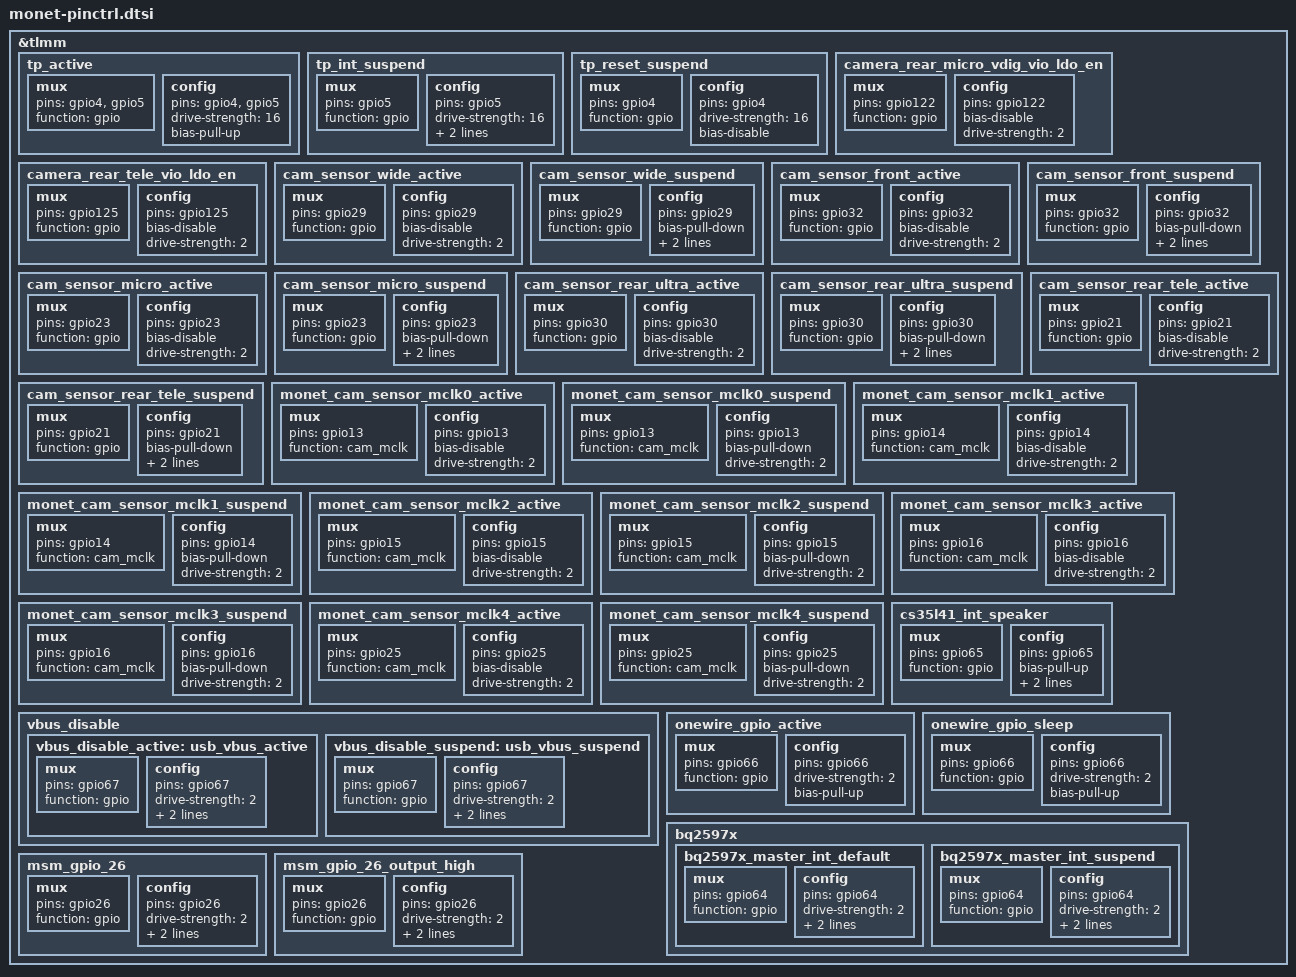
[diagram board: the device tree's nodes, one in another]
/*For J9 pinctrl overlay*/

&tlmm {
	tp_active: tp_active {
		mux {
				pins = "gpio4", "gpio5";
				function = "gpio";
		};

		config {
				pins = "gpio4", "gpio5";
				drive-strength = <16>;
				bias-pull-up;
		};
	};

	tp_int_suspend: tp_int_suspend {
		mux {
				pins = "gpio5";
				function = "gpio";
		};
		config {
				pins = "gpio5";
				drive-strength = <16>;
				bias-pull-up;
				input-enable;
		};
	};

	tp_reset_suspend: tp_reset_suspend {
		mux {
				pins = "gpio4";
				function = "gpio";
		};
		config {
				pins = "gpio4";
				drive-strength = <16>;
				bias-disable;
		};
	};

	camera_rear_micro_vdig_vio_ldo_en: camera_rear_micro_vdig_vio_ldo_en {
		mux {
			pins = "gpio122";
			function = "gpio";
		};

		config {
			pins = "gpio122";
			bias-disable; /* No PULL */
			drive-strength = <2>; /* 2 MA */
		};
	};

	camera_rear_tele_vio_ldo_en: camera_rear_tele_vio_ldo_en {
		mux {
			pins = "gpio125";
			function = "gpio";
		};

		config {
			pins = "gpio125";
			bias-disable; /* No PULL */
			drive-strength = <2>; /* 2 MA */
		};
	};

	cam_sensor_wide_active: cam_sensor_wide_active {
		/* RESET WIDE */
		mux {
			pins = "gpio29";
			function = "gpio";
		};

		config {
			pins = "gpio29";
			bias-disable; /* No PULL */
			drive-strength = <2>; /* 2 MA */
		};
	};

	cam_sensor_wide_suspend: cam_sensor_wide_suspend {
		mux {
			pins = "gpio29";
			function = "gpio";
		};

		config {
			pins = "gpio29";
			bias-pull-down; /* PULL DOWN */
			drive-strength = <2>; /* 2 MA */
			output-low;
		};
	};

	cam_sensor_front_active: cam_sensor_front_active {
		/* RESET FRONT */
		mux {
			pins = "gpio32";
			function = "gpio";
		};

		config {
			pins = "gpio32";
			bias-disable; /* No PULL */
			drive-strength = <2>; /* 2 MA */
		};
	};

	cam_sensor_front_suspend: cam_sensor_front_suspend {
		/* RESET FRONT */
		mux {
			pins = "gpio32";
			function = "gpio";
		};

		config {
			pins = "gpio32";
			bias-pull-down; /* PULL DOWN */
			drive-strength = <2>; /* 2 MA */
			output-low;
		};
	};

	cam_sensor_micro_active: cam_sensor_micro_active {
		/* RESET MICRO */
		mux {
			pins = "gpio23";
			function = "gpio";
		};

		config {
			pins = "gpio23";
			bias-disable; /* No PULL */
			drive-strength = <2>; /* 2 MA */
		};
	};

	cam_sensor_micro_suspend: cam_sensor_micro_suspend {
		/* RESET MICRO */
		mux {
			pins = "gpio23";
			function = "gpio";
		};

		config {
			pins = "gpio23";
			bias-pull-down; /* PULL DOWN */
			drive-strength = <2>; /* 2 MA */
			output-low;
		};
	};

	cam_sensor_rear_ultra_active: cam_sensor_rear_ultra_active {
		/* RESET ULTRA */
		mux {
			pins = "gpio30";
			function = "gpio";
		};

		config {
			pins = "gpio30";
			bias-disable; /* No PULL */
			drive-strength = <2>; /* 2 MA */
		};
	};

	cam_sensor_rear_ultra_suspend: cam_sensor_rear_ultra_suspend {
		/* RESET ULTRA */
		mux {
			pins = "gpio30";
			function = "gpio";
		};

		config {
			pins = "gpio30";
			bias-pull-down; /* PULL DOWN */
			drive-strength = <2>; /* 2 MA */
			output-low;
		};
	};

	cam_sensor_rear_tele_active: cam_sensor_rear_tele_active {
		/* RESET TELE */
		mux {
			pins = "gpio21";
			function = "gpio";
		};

		config {
			pins = "gpio21";
			bias-disable; /* No PULL */
			drive-strength = <2>; /* 2 MA */
		};
	};

	cam_sensor_rear_tele_suspend: cam_sensor_rear_tele_suspend {
		/* RESET TELE */
		mux {
			pins = "gpio21";
			function = "gpio";
		};

		config {
			pins = "gpio21";
			bias-pull-down; /* PULL DOWN */
			drive-strength = <2>; /* 2 MA */
			output-low;
		};
	};

	monet_cam_sensor_mclk0_active: monet_cam_sensor_mclk0_active {
		/* MCLK0 */
		mux {
			pins = "gpio13";
			function = "cam_mclk";
		};

		config {
			pins = "gpio13";
			bias-disable; /* No PULL */
			drive-strength = <2>; /* 2 MA */
		};
	};

	monet_cam_sensor_mclk0_suspend: monet_cam_sensor_mclk0_suspend {
		/* MCLK0 */
		mux {
			pins = "gpio13";
			function = "cam_mclk";
		};

		config {
			pins = "gpio13";
			bias-pull-down; /* PULL DOWN */
			drive-strength = <2>; /* 2 MA */
		};
	};

	monet_cam_sensor_mclk1_active: monet_cam_sensor_mclk1_active {
		/* MCLK1 */
		mux {
			pins = "gpio14";
			function = "cam_mclk";
		};

		config {
			pins = "gpio14";
			bias-disable; /* No PULL */
			drive-strength = <2>; /* 2 MA */
		};
	};

	monet_cam_sensor_mclk1_suspend: monet_cam_sensor_mclk1_suspend {
		/* MCLK1 */
		mux {
			pins = "gpio14";
			function = "cam_mclk";
		};

		config {
			pins = "gpio14";
			bias-pull-down; /* PULL DOWN */
			drive-strength = <2>; /* 2 MA */
		};
	};

	monet_cam_sensor_mclk2_active: monet_cam_sensor_mclk2_active {
		/* MCLK2 */
		mux {
			pins = "gpio15";
			function = "cam_mclk";
		};

		config {
			pins = "gpio15";
			bias-disable; /* No PULL */
			drive-strength = <2>; /* 2 MA */
		};
	};

	monet_cam_sensor_mclk2_suspend: monet_cam_sensor_mclk2_suspend {
		/* MCLK2 */
		mux {
			pins = "gpio15";
			function = "cam_mclk";
		};

		config {
			pins = "gpio15";
			bias-pull-down; /* PULL DOWN */
			drive-strength = <2>; /* 2 MA */
		};
	};

	monet_cam_sensor_mclk3_active: monet_cam_sensor_mclk3_active {
		/* MCLK3 */
		mux {
			pins = "gpio16";
			function = "cam_mclk";
		};

		config {
			pins = "gpio16";
			bias-disable; /* No PULL */
			drive-strength = <2>; /* 2 MA */
		};
	};

	monet_cam_sensor_mclk3_suspend: monet_cam_sensor_mclk3_suspend {
		/* MCLK3 */
		mux {
			pins = "gpio16";
			function = "cam_mclk";
		};

		config {
			pins = "gpio16";
			bias-pull-down; /* PULL DOWN */
			drive-strength = <2>; /* 2 MA */
		};
	};

	monet_cam_sensor_mclk4_active: monet_cam_sensor_mclk4_active {
		/* MCLK4 */
		mux {
			pins = "gpio25";
			function = "cam_mclk";
		};

		config {
			pins = "gpio25";
			bias-disable; /* No PULL */
			drive-strength = <2>; /* 2 MA */
		};
	};

	monet_cam_sensor_mclk4_suspend: monet_cam_sensor_mclk4_suspend {
		/* MCLK4 */
		mux {
			pins = "gpio25";
			function = "cam_mclk";
		};

		config {
			pins = "gpio25";
			bias-pull-down; /* PULL DOWN */
			drive-strength = <2>; /* 2 MA */
		};
	};

	cs35l41_int_speaker: cs35l41_int_speaker {
		mux {
			pins = "gpio65";
			function = "gpio";
		};
		config {
			pins = "gpio65";
			bias-pull-up;
			drive-strength = <8>;
			input-enable;
		};
	};

	vbus_disable {
		vbus_disable_active: usb_vbus_active {
			/* active state */
			mux {
				pins = "gpio67";
				function = "gpio";
			};

			config {
				pins = "gpio67";
				drive-strength = <2>; /* 2 MA */
				bias-pull-up;
				output-high;
			};
		};

		vbus_disable_suspend: usb_vbus_suspend {
			mux {
				pins = "gpio67";
				function = "gpio";
			};

			config {
				pins = "gpio67";
				drive-strength = <2>; /* 2 MA */
				bias-pull-down;
				output-low;
			};
		};
	};

	onewire_gpio_active: onewire_gpio_active {
		mux {
			pins = "gpio66";
			function = "gpio";
		};

		config {
			pins = "gpio66";
			drive-strength = <2>;
			bias-pull-up; /* No PULL */
		};
	};

	onewire_gpio_sleep: onewire_gpio_sleep {
		mux {
			pins = "gpio66";
			function = "gpio";
		};

		config {
			pins = "gpio66";
			drive-strength = <2>;
			bias-pull-up;
		};
	};

	bq2597x {
		bq2597x_master_int_default: bq2597x_master_int_default {
			/* active state */
			mux {
				/* GPIO 64 is used for bq25970 master ic interrupt usage */
				pins = "gpio64";
				function = "gpio";
			};

			config {
				pins = "gpio64";
				drive-strength = <2>; /* 2 MA */
				bias-pull-up;
				input-enable;
			};
		};

		bq2597x_master_int_suspend: bq2597x_master_int_suspend {
			/* sleep state */
			mux {
				/* GPIO 64 is used for bq25970 master ic interrupt usage */
				pins = "gpio64";
				function = "gpio";
			};

			config {
				pins = "gpio64";
				drive-strength = <2>; /* 2 MA */
				bias-pull-up;
				input-enable;
			};
		};
	};

	/* GPIO_26 : AW8624_RESET_N */
	msm_gpio_26: msm_gpio_26 {
		mux {
			 pins = "gpio26";
			 function = "gpio";
		};

		config {
			pins = "gpio26";
			drive-strength = <2>;
			bias-disable;
			output-low;
		};
	};
	/* GPIO_26 : AW8624_RESET_N, state device active*/
	msm_gpio_26_output_high: msm_gpio_26_output_high {
		mux {
			pins = "gpio26";
			function = "gpio";
		};

		config {
			pins = "gpio26";
			drive-strength = <2>;
			bias-disable;
			output-high;
		};
	};
};
